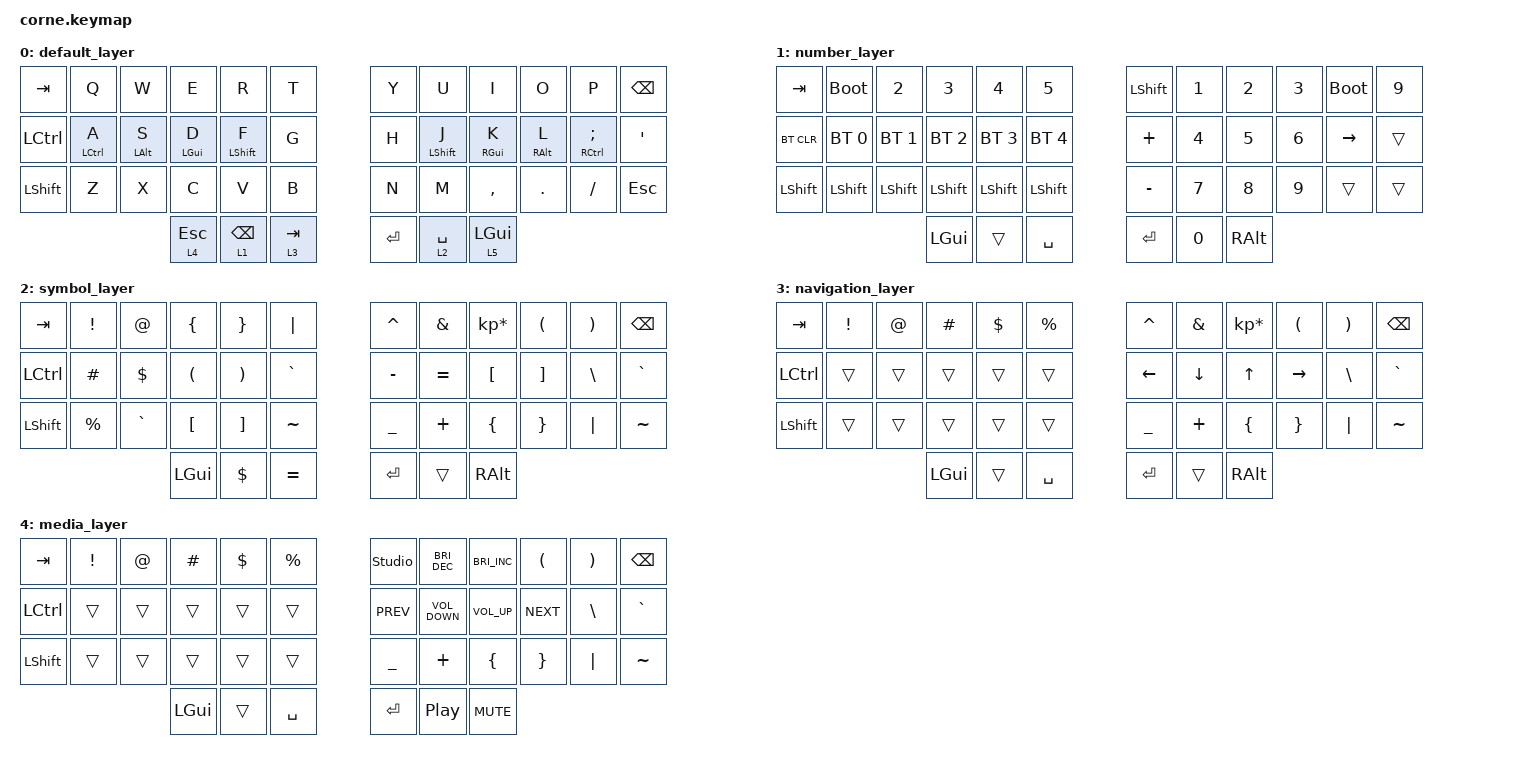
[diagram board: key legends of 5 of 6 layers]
/*
 * Copyright (c) 2020 The ZMK Contributors
 *
 * SPDX-License-Identifier: MIT
 */

#include <behaviors.dtsi>
#include <dt-bindings/zmk/keys.h>
#include <dt-bindings/zmk/bt.h>
#include <dt-bindings/zmk/outputs.h>

/ {
    behaviors {
        hm: homerow_mods {
            compatible = "zmk,behavior-hold-tap";
            #binding-cells = <2>;
            tapping-term-ms = <300>;
            quick-tap-ms = <0>;
            flavor = "tap-preferred";
            bindings = <&kp>, <&kp>;
        };
    };

    combos {
        compatible = "zmk,combos";
        combo_apos {
            timeout-ms = <50>;
            key-positions = <21 22>;
            bindings = <&kp SQT>;
        };
        combo_soft_off {
            timeout-ms = <50>;
            key-positions = <10 11>;
            bindings = <&soft_off>;
        };
    };


        keymap {
                compatible = "zmk,keymap";

                default_layer {
// -----------------------------------------------------------------------------------------
// |  TAB |  Q  |  W  |  E  |  R  |  T  |   |  Y  |  U   |  I  |  O  |  P  | BKSP |
// | CTRL |  A  |  S  |  D  |  F  |  G  |   |  H  |  J   |  K  |  L  |  ;  |  '   |
// | SHFT |  Z  |  X  |  C  |  V  |  B  |   |  N  |  M   |  ,  |  .  |  /  | ESC  |
//                    | ESC | SPC | TAB |   | ETR | BKSP | GUI |
                        bindings = <
   &kp TAB   &kp Q &kp W &kp E &kp R &kp T &kp Y &kp U  &kp I &kp O &kp P &kp BSPC
   &kp LCTRL &hm LCTRL A &hm LALT S &hm LGUI D &hm LSHFT F &kp G   &kp H &hm LSHFT J &hm RGUI K &hm RALT L &hm RCTRL SEMI &kp SQT
   &kp LSHFT &kp Z &kp X &kp C &kp V &kp B &kp N &kp M  &kp COMMA &kp DOT &kp FSLH &kp ESC
                   &lt 4 ESC &lt 1 BACKSPACE &lt 3 TAB &kp ENTER &lt 2 SPACE &lt 5 LGUI
                        >;
                };
                number_layer {
// -----------------------------------------------------------------------------------------
// |  TAB |  1  |  2  |  3  |  4  |  5  |   |  1  |  2  |  3  |  9  |  &bootloader  | BKSP |
// | BTCLR| BT1 | BT2 | BT3 | BT4 | BT5 |   |  4  |  5  |  6  | RGT |     |      |
// | SHFT |     |     |     |     |     |   |  7  |  8  |  9  |     |     |      |
//                    | GUI |     | SPC |   | ENT |  0  | ALT |
                        bindings = <
   &kp TAB &bootloader &kp N2 &kp N3 &kp N4 &kp N5 &kp LSHFT &kp N1 &kp N2 &kp N3 &bootloader &kp N9
   &bt BT_CLR &bt BT_SEL 0 &bt BT_SEL 1 &bt BT_SEL 2 &bt BT_SEL 3 &bt BT_SEL 4 &kp PLUS &kp N4 &kp N5 &kp N6 &kp RIGHT &trans 
   &kp LSHFT &kp LSHFT &kp LSHFT &kp LSHFT &kp LSHFT &kp LSHFT &kp MINUS &kp N7 &kp N8 &kp N9 &trans &trans
                                    &kp LGUI &trans &kp SPACE &kp RET &kp N0 &kp RALT
                        >;
                };
                symbol_layer {
// -----------------------------------------------------------------------------------------
// |  TAB |  !  |  @  |  #  |  $  |  %  |   |  ^  |  &  |  *  |  (  |  )  | BKSP |
// | CTRL |     |     |     |     |     |   |  -  |  =  |  [  |  ]  |  \  |  `   |
// | SHFT |     |     |     |     |     |   |  _  |  +  |  {  |  }  | "|" |  ~   |
//                    | GUI |     | SPC |   | ENT |     | ALT |
                        bindings = <
   &kp  TAB  &kp EXCL &kp AT &kp LBRC &kp RBRC &kp PIPE   &kp CARET &kp AMPS  &kp KP_MULTIPLY &kp LPAR &kp RPAR &kp BSPC
   &kp LCTRL &kp HASH &kp DLLR &kp LPAR &kp RPAR   &kp GRAVE       &kp MINUS &kp EQUAL &kp LBKT        &kp RBKT &kp BSLH &kp GRAVE
   &kp LSHFT &kp PRCNT &kp GRAVE &kp LBKT &kp RBKT   &kp TILDE      &kp UNDER &kp PLUS  &kp LBRC        &kp RBRC &kp PIPE &kp TILDE
                             &kp LGUI &kp DLLR &kp EQUAL   &kp RET   &trans    &kp RALT
                        >;
                };
                navigation_layer {
// -----------------------------------------------------------------------------------------
// |  TAB |  !  |  @  |  #  |  $  |  %  |   |  ^  |  &  |  *  |  (  |  )  | BKSP |
// | CTRL |     |     |     |     |     |   |  -  |  =  |  [  |  ]  |  \  |  `   |
// | SHFT |     |     |     |     |     |   |  _  |  +  |  {  |  }  | "|" |  ~   |
//                    | GUI |     | SPC |   | ENT |     | ALT |
                        bindings = <
   &kp  TAB  &kp EXCL &kp AT &kp HASH &kp DLLR &kp PRCNT   &kp CARET &kp AMPS  &kp KP_MULTIPLY &kp LPAR &kp RPAR &kp BSPC
   &kp LCTRL &trans   &trans &trans   &trans   &trans      &kp LEFT &kp DOWN &kp UP &kp RIGHT &kp BSLH &kp GRAVE
   &kp LSHFT &trans   &trans &trans   &trans   &trans      &kp UNDER &kp PLUS  &kp LBRC        &kp RBRC &kp PIPE &kp TILDE
                             &kp LGUI &trans   &kp SPACE   &kp RET   &trans    &kp RALT
                        >;
                };
                media_layer {
// -----------------------------------------------------------------------------------------
// |  TAB |  !  |  @  |  #  |  $  |  %  |   |  ^  |  &  |  *  |  (  |  )  | BKSP |
// | CTRL |     |     |     |     |     |   |  -  |  =  |  [  |  ]  |  \  |  `   |
// | SHFT |     |     |     |     |     |   |  _  |  +  |  {  |  }  | "|" |  ~   |
//                    | GUI |     | SPC |   | ENT |     | ALT |
                        bindings = <
   &kp  TAB  &kp EXCL &kp AT &kp HASH &kp DLLR &kp PRCNT   &studio_unlock &kp C_BRIGHTNESS_DEC &kp C_BRIGHTNESS_INC &kp LPAR &kp RPAR &kp BSPC
   &kp LCTRL &trans   &trans &trans   &trans   &trans      &kp C_PREV &kp K_VOLUME_DOWN &kp K_VOLUME_UP &kp C_NEXT &kp BSLH &kp GRAVE
   &kp LSHFT &trans   &trans &trans   &trans   &trans      &kp UNDER &kp PLUS  &kp LBRC        &kp RBRC &kp PIPE &kp TILDE
                             &kp LGUI &trans   &kp SPACE   &kp RET  &kp C_PLAY_PAUSE &kp C_MUTE
                        >;
                };

                keybr_layer {
// -----------------------------------------------------------------------------------------
// |  TAB |  !  |  @  |  #  |  $  |  %  |   |  ^  |  &  |  *  |  (  |  )  | BKSP |
// | CTRL |     |     |     |     |     |   |  -  |  =  |  [  |  ]  |  \  |  `   |
// | SHFT |     |     |     |     |     |   |  _  |  +  |  {  |  }  | "|" |  ~   |
//                    | GUI |     | SPC |   | ENT |     | ALT |
                        bindings = <
   &kp  TAB  &bt BT_CLR &bt BT_CLR_ALL &out OUT_TOG &sys_reset &bootloader   &bootloader &sys_reset &kp C_BRIGHTNESS_INC &kp LPAR &kp RPAR &kp BSPC
   &kp LCTRL &bt BT_SEL 0 &bt BT_SEL 1 &bt BT_SEL 2  &bt BT_SEL 3  &bt BT_SEL 4 &kp K_VOLUME_UP &kp K_VOLUME_UP &kp C_NEXT &kp BSLH &kp GRAVE
   &kp LSHFT &trans   &trans &trans   &trans   &trans      &kp UNDER &kp PLUS  &kp LBRC        &kp RBRC &kp PIPE &kp TILDE
                             &kp LGUI &trans   &kp SPACE   &kp RET  &kp C_PLAY_PAUSE &kp C_MUTE
                        >;
                };

        };
};

